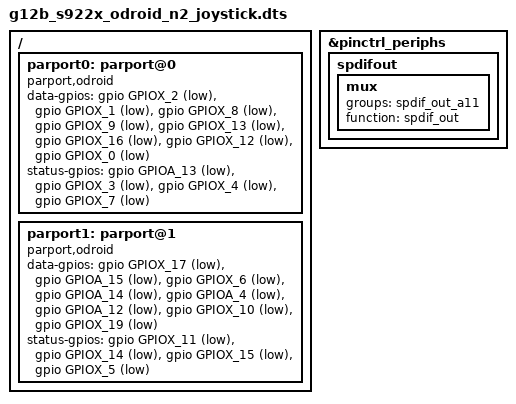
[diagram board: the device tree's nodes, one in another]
#include "g12b_s922x_odroid_n2plus.dts"

/{
	parport0: parport@0 {
		compatible = "parport,odroid";
		status = "okay";

		data-gpios = <&gpio GPIOX_2 GPIO_ACTIVE_LOW>,
			<&gpio GPIOX_1 GPIO_ACTIVE_LOW>,
			<&gpio GPIOX_8 GPIO_ACTIVE_LOW>,
			<&gpio GPIOX_9 GPIO_ACTIVE_LOW>,
			<&gpio GPIOX_13 GPIO_ACTIVE_LOW>,
			<&gpio GPIOX_16 GPIO_ACTIVE_LOW>,
			<&gpio GPIOX_12 GPIO_ACTIVE_LOW>,
			<&gpio GPIOX_0 GPIO_ACTIVE_LOW>;

		status-gpios = <&gpio GPIOA_13 GPIO_ACTIVE_LOW>,
			<&gpio GPIOX_3 GPIO_ACTIVE_LOW>,
			<&gpio GPIOX_4 GPIO_ACTIVE_LOW>,
			<&gpio GPIOX_7 GPIO_ACTIVE_LOW>;
	};

	parport1: parport@1 {
		compatible = "parport,odroid";
		status = "okay";

		data-gpios = <&gpio GPIOX_17 GPIO_ACTIVE_LOW>,
			<&gpio GPIOA_15 GPIO_ACTIVE_LOW>,
			<&gpio GPIOX_6 GPIO_ACTIVE_LOW>,
			<&gpio GPIOA_14 GPIO_ACTIVE_LOW>,
			<&gpio GPIOA_4 GPIO_ACTIVE_LOW>,
			<&gpio GPIOA_12 GPIO_ACTIVE_LOW>,
			<&gpio GPIOX_10 GPIO_ACTIVE_LOW>,
			<&gpio GPIOX_19 GPIO_ACTIVE_LOW>;

		status-gpios = <&gpio GPIOX_11 GPIO_ACTIVE_LOW>,
			<&gpio GPIOX_14 GPIO_ACTIVE_LOW>,
			<&gpio GPIOX_15 GPIO_ACTIVE_LOW>,
			<&gpio GPIOX_5 GPIO_ACTIVE_LOW>;
	};
};

&pinctrl_periphs {
	spdifout: spdifout {
		mux {/* GPIOA_11 */
			groups = "spdif_out_a11";
			function = "spdif_out";
		};
	};
};
